VERSION ""

NS_ :

BS_:
BU_: ADU LBC Inverter
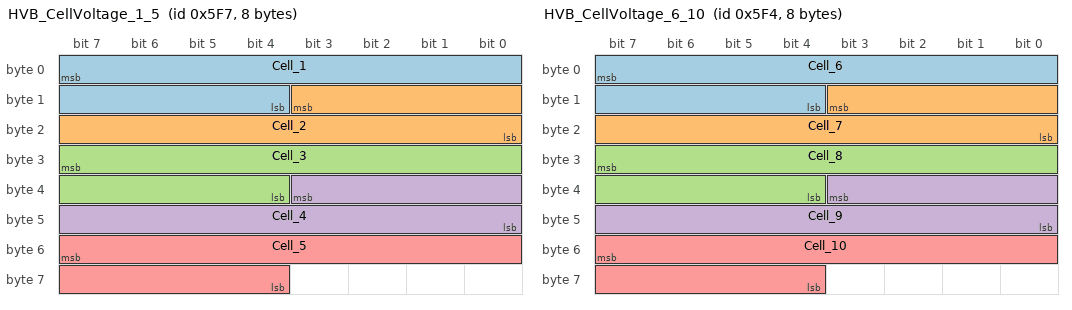
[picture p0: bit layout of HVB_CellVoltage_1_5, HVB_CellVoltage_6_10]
BO_ 1527 HVB_CellVoltage_1_5: 8 LBC
   SG_ Cell_1 : 7|12@0+ (0.001,2) [0|1] "Volts" LBC
   SG_ Cell_2 : 11|12@0+ (0.001,2) [0|1] "Volts" LBC
   SG_ Cell_3 : 31|12@0+ (0.001,2) [0|1] "Volts" LBC
   SG_ Cell_4 : 35|12@0+ (0.001,2) [0|1] "Volts" LBC
   SG_ Cell_5 : 55|12@0+ (0.001,2) [0|1] "Volts" LBC

BO_ 1524 HVB_CellVoltage_6_10: 8 LBC
   SG_ Cell_6 : 7|12@0+ (0.001,2) [0|1] "Volts" LBC
   SG_ Cell_7 : 11|12@0+ (0.001,2) [0|1] "Volts" LBC
   SG_ Cell_8 : 31|12@0+ (0.001,2) [0|1] "Volts" LBC
   SG_ Cell_9 : 35|12@0+ (0.001,2) [0|1] "Volts" LBC
   SG_ Cell_10 : 55|12@0+ (0.001,2) [0|1] "Volts" LBC

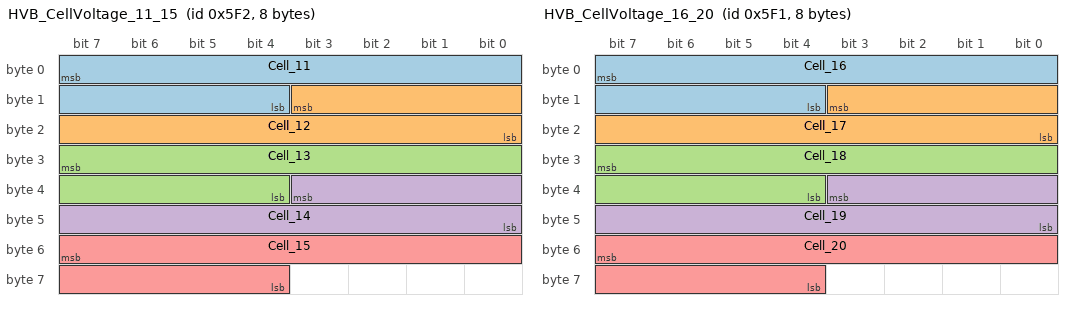
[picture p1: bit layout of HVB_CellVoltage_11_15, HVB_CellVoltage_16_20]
BO_ 1522 HVB_CellVoltage_11_15: 8 LBC
   SG_ Cell_11 : 7|12@0+ (0.001,2) [0|1] "Volts" LBC
   SG_ Cell_12 : 11|12@0+ (0.001,2) [0|1] "Volts" LBC
   SG_ Cell_13 : 31|12@0+ (0.001,2) [0|1] "Volts" LBC
   SG_ Cell_14 : 35|12@0+ (0.001,2) [0|1] "Volts" LBC
   SG_ Cell_15 : 55|12@0+ (0.001,2) [0|1] "Volts" LBC

BO_ 1521 HVB_CellVoltage_16_20: 8 LBC
   SG_ Cell_16 : 7|12@0+ (0.001,2) [0|1] "Volts" LBC
   SG_ Cell_17 : 11|12@0+ (0.001,2) [0|1] "Volts" LBC
   SG_ Cell_18 : 31|12@0+ (0.001,2) [0|1] "Volts" LBC
   SG_ Cell_19 : 35|12@0+ (0.001,2) [0|1] "Volts" LBC
   SG_ Cell_20 : 55|12@0+ (0.001,2) [0|1] "Volts" LBC

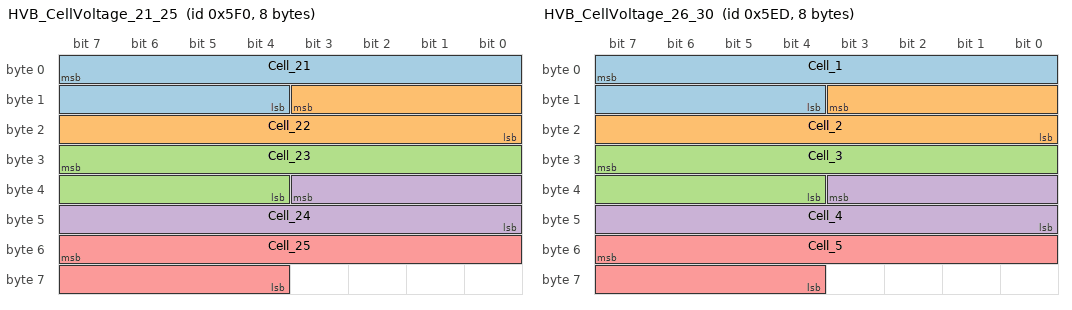
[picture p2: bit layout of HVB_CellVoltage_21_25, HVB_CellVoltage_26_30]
BO_ 1520 HVB_CellVoltage_21_25: 8 LBC
   SG_ Cell_21 : 7|12@0+ (0.001,2) [0|1] "Volts" LBC
   SG_ Cell_22 : 11|12@0+ (0.001,2) [0|1] "Volts" LBC
   SG_ Cell_23 : 31|12@0+ (0.001,2) [0|1] "Volts" LBC
   SG_ Cell_24 : 35|12@0+ (0.001,2) [0|1] "Volts" LBC
   SG_ Cell_25 : 55|12@0+ (0.001,2) [0|1] "Volts" LBC

BO_ 1517 HVB_CellVoltage_26_30: 8 LBC
   SG_ Cell_1 : 7|12@0+ (0.001,2) [0|1] "Volts" LBC
   SG_ Cell_2 : 11|12@0+ (0.001,2) [0|1] "Volts" LBC
   SG_ Cell_3 : 31|12@0+ (0.001,2) [0|1] "Volts" LBC
   SG_ Cell_4 : 35|12@0+ (0.001,2) [0|1] "Volts" LBC
   SG_ Cell_5 : 55|12@0+ (0.001,2) [0|1] "Volts" LBC

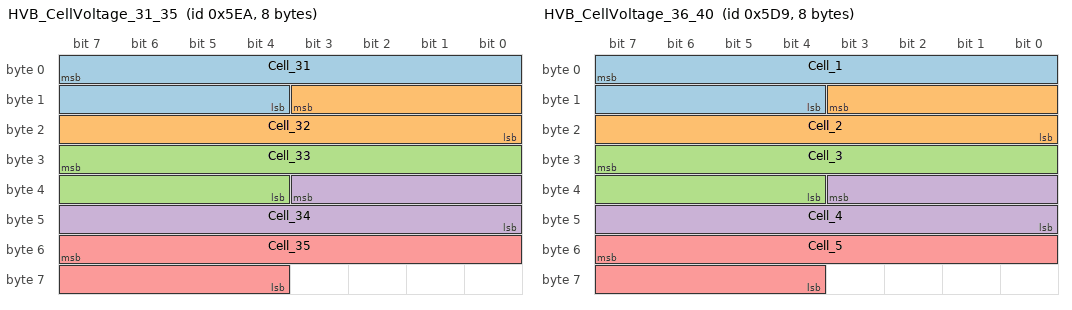
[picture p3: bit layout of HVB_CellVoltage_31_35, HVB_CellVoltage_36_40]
BO_ 1514 HVB_CellVoltage_31_35: 8 LBC
   SG_ Cell_31 : 7|12@0+ (0.001,2) [0|1] "Volts" LBC
   SG_ Cell_32 : 11|12@0+ (0.001,2) [0|1] "Volts" LBC
   SG_ Cell_33 : 31|12@0+ (0.001,2) [0|1] "Volts" LBC
   SG_ Cell_34 : 35|12@0+ (0.001,2) [0|1] "Volts" LBC
   SG_ Cell_35 : 55|12@0+ (0.001,2) [0|1] "Volts" LBC

BO_ 1497 HVB_CellVoltage_36_40: 8 LBC
   SG_ Cell_1 : 7|12@0+ (0.001,2) [0|1] "Volts" LBC
   SG_ Cell_2 : 11|12@0+ (0.001,2) [0|1] "Volts" LBC
   SG_ Cell_3 : 31|12@0+ (0.001,2) [0|1] "Volts" LBC
   SG_ Cell_4 : 35|12@0+ (0.001,2) [0|1] "Volts" LBC
   SG_ Cell_5 : 55|12@0+ (0.001,2) [0|1] "Volts" LBC

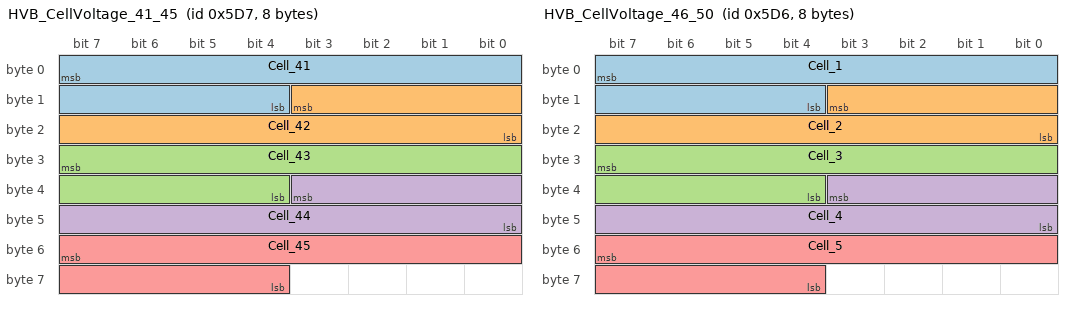
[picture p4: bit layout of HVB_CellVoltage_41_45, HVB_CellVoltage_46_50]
BO_ 1495 HVB_CellVoltage_41_45: 8 LBC
   SG_ Cell_41 : 7|12@0+ (0.001,2) [0|1] "Volts" LBC
   SG_ Cell_42 : 11|12@0+ (0.001,2) [0|1] "Volts" LBC
   SG_ Cell_43 : 31|12@0+ (0.001,2) [0|1] "Volts" LBC
   SG_ Cell_44 : 35|12@0+ (0.001,2) [0|1] "Volts" LBC
   SG_ Cell_45 : 55|12@0+ (0.001,2) [0|1] "Volts" LBC

BO_ 1494 HVB_CellVoltage_46_50: 8 LBC
   SG_ Cell_1 : 7|12@0+ (0.001,2) [0|1] "Volts" LBC
   SG_ Cell_2 : 11|12@0+ (0.001,2) [0|1] "Volts" LBC
   SG_ Cell_3 : 31|12@0+ (0.001,2) [0|1] "Volts" LBC
   SG_ Cell_4 : 35|12@0+ (0.001,2) [0|1] "Volts" LBC
   SG_ Cell_5 : 55|12@0+ (0.001,2) [0|1] "Volts" LBC

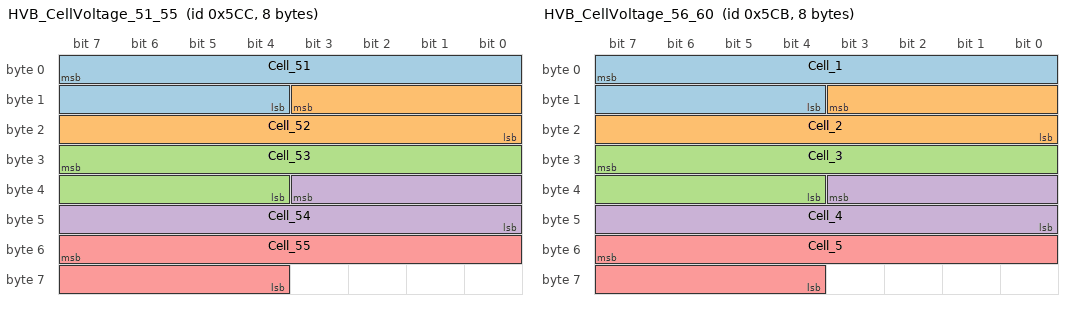
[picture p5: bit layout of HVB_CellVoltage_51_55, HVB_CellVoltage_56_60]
BO_ 1484 HVB_CellVoltage_51_55: 8 LBC
   SG_ Cell_51 : 7|12@0+ (0.001,2) [0|1] "Volts" LBC
   SG_ Cell_52 : 11|12@0+ (0.001,2) [0|1] "Volts" LBC
   SG_ Cell_53 : 31|12@0+ (0.001,2) [0|1] "Volts" LBC
   SG_ Cell_54 : 35|12@0+ (0.001,2) [0|1] "Volts" LBC
   SG_ Cell_55 : 55|12@0+ (0.001,2) [0|1] "Volts" LBC

BO_ 1483 HVB_CellVoltage_56_60: 8 LBC
   SG_ Cell_1 : 7|12@0+ (0.001,2) [0|1] "Volts" LBC
   SG_ Cell_2 : 11|12@0+ (0.001,2) [0|1] "Volts" LBC
   SG_ Cell_3 : 31|12@0+ (0.001,2) [0|1] "Volts" LBC
   SG_ Cell_4 : 35|12@0+ (0.001,2) [0|1] "Volts" LBC
   SG_ Cell_5 : 55|12@0+ (0.001,2) [0|1] "Volts" LBC

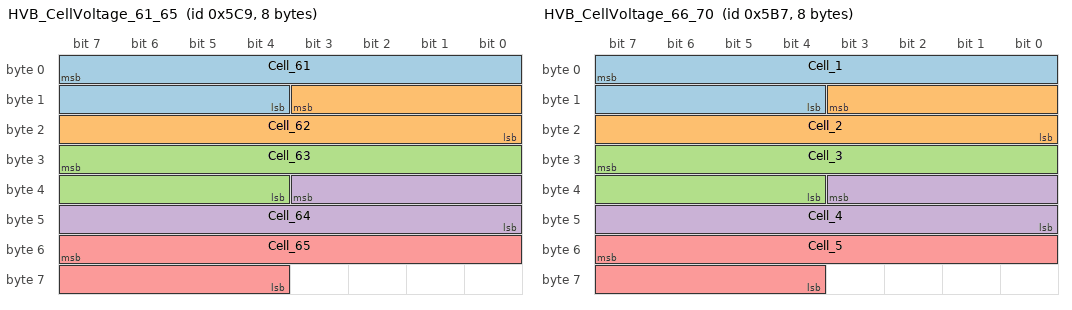
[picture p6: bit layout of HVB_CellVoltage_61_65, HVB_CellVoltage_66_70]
BO_ 1481 HVB_CellVoltage_61_65: 8 LBC
   SG_ Cell_61 : 7|12@0+ (0.001,2) [0|1] "Volts" LBC
   SG_ Cell_62 : 11|12@0+ (0.001,2) [0|1] "Volts" LBC
   SG_ Cell_63 : 31|12@0+ (0.001,2) [0|1] "Volts" LBC
   SG_ Cell_64 : 35|12@0+ (0.001,2) [0|1] "Volts" LBC
   SG_ Cell_65 : 55|12@0+ (0.001,2) [0|1] "Volts" LBC

BO_ 1463 HVB_CellVoltage_66_70: 8 LBC
   SG_ Cell_1 : 7|12@0+ (0.001,2) [0|1] "Volts" LBC
   SG_ Cell_2 : 11|12@0+ (0.001,2) [0|1] "Volts" LBC
   SG_ Cell_3 : 31|12@0+ (0.001,2) [0|1] "Volts" LBC
   SG_ Cell_4 : 35|12@0+ (0.001,2) [0|1] "Volts" LBC
   SG_ Cell_5 : 55|12@0+ (0.001,2) [0|1] "Volts" LBC

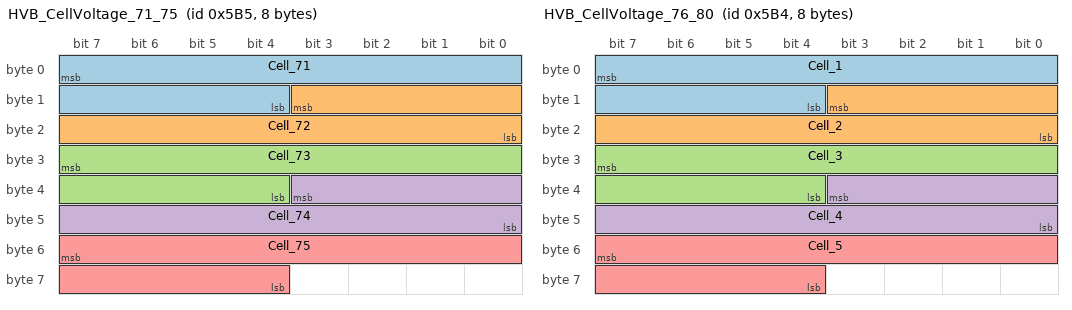
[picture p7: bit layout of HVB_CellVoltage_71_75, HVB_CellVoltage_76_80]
BO_ 1461 HVB_CellVoltage_71_75: 8 LBC
   SG_ Cell_71 : 7|12@0+ (0.001,2) [0|1] "Volts" LBC
   SG_ Cell_72 : 11|12@0+ (0.001,2) [0|1] "Volts" LBC
   SG_ Cell_73 : 31|12@0+ (0.001,2) [0|1] "Volts" LBC
   SG_ Cell_74 : 35|12@0+ (0.001,2) [0|1] "Volts" LBC
   SG_ Cell_75 : 55|12@0+ (0.001,2) [0|1] "Volts" LBC

BO_ 1460 HVB_CellVoltage_76_80: 8 LBC
   SG_ Cell_1 : 7|12@0+ (0.001,2) [0|1] "Volts" LBC
   SG_ Cell_2 : 11|12@0+ (0.001,2) [0|1] "Volts" LBC
   SG_ Cell_3 : 31|12@0+ (0.001,2) [0|1] "Volts" LBC
   SG_ Cell_4 : 35|12@0+ (0.001,2) [0|1] "Volts" LBC
   SG_ Cell_5 : 55|12@0+ (0.001,2) [0|1] "Volts" LBC

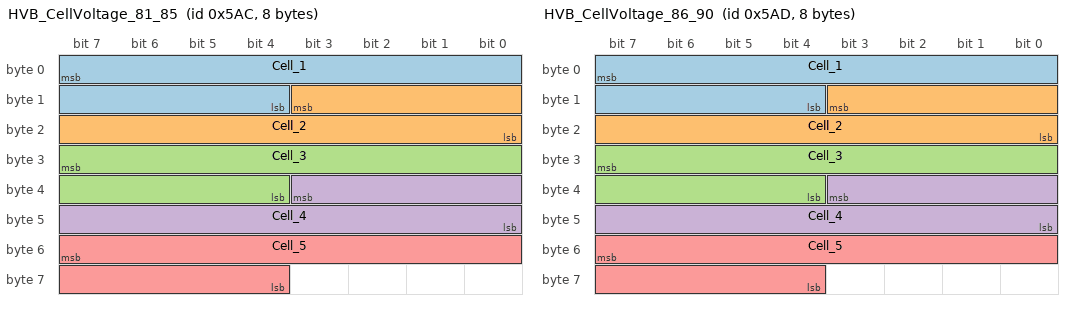
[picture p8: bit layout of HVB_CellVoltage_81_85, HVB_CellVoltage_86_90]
BO_ 1452 HVB_CellVoltage_81_85: 8 LBC
   SG_ Cell_1 : 7|12@0+ (0.001,2) [0|1] "Volts" LBC
   SG_ Cell_2 : 11|12@0+ (0.001,2) [0|1] "Volts" LBC
   SG_ Cell_3 : 31|12@0+ (0.001,2) [0|1] "Volts" LBC
   SG_ Cell_4 : 35|12@0+ (0.001,2) [0|1] "Volts" LBC
   SG_ Cell_5 : 55|12@0+ (0.001,2) [0|1] "Volts" LBC

BO_ 1453 HVB_CellVoltage_86_90: 8 LBC
   SG_ Cell_1 : 7|12@0+ (0.001,2) [0|1] "Volts" LBC
   SG_ Cell_2 : 11|12@0+ (0.001,2) [0|1] "Volts" LBC
   SG_ Cell_3 : 31|12@0+ (0.001,2) [0|1] "Volts" LBC
   SG_ Cell_4 : 35|12@0+ (0.001,2) [0|1] "Volts" LBC
   SG_ Cell_5 : 55|12@0+ (0.001,2) [0|1] "Volts" LBC

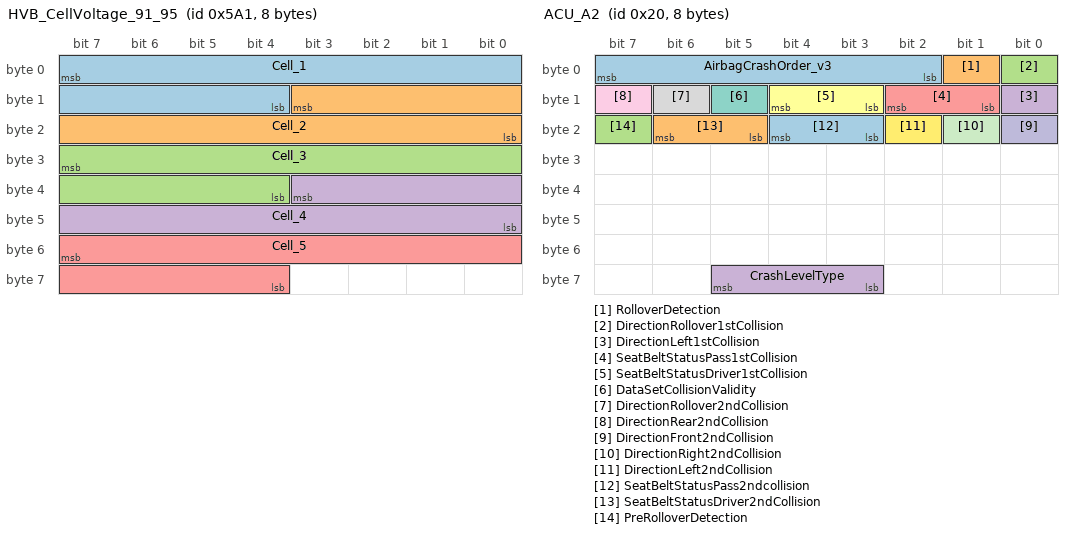
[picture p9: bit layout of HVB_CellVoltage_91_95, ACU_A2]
BO_ 1441 HVB_CellVoltage_91_95: 8 LBC
   SG_ Cell_1 : 7|12@0+ (0.001,2) [0|1] "Volts" LBC
   SG_ Cell_2 : 11|12@0+ (0.001,2) [0|1] "Volts" LBC
   SG_ Cell_3 : 31|12@0+ (0.001,2) [0|1] "Volts" LBC
   SG_ Cell_4 : 35|12@0+ (0.001,2) [0|1] "Volts" LBC
   SG_ Cell_5 : 55|12@0+ (0.001,2) [0|1] "Volts" LBC

BO_ 1501 HVB_CellVoltage_96: 8 LBC
   SG_ Cell_96 : 7|12@0+ (0.001,2) [0|1] "Volts" LBC

BO_ 32 ACU_A2: 8 ADU
   SG_ AirbagCrashOrder_v3 : 7|6@0+ (1,0) [0|1] "" Vector__XXX
   SG_ RolloverDetection : 1|1@0+ (1,0) [0|1] "" Vector__XXX
   SG_ DirectionRollover1stCollision : 0|1@0+ (1,0) [0|1] "" Vector__XXX
   SG_ DirectionLeft1stCollision : 8|1@0+ (1,0) [0|1] "" Vector__XXX
   SG_ SeatBeltStatusPass1stCollision : 10|2@0+ (1,0) [0|1] "" Vector__XXX
   SG_ SeatBeltStatusDriver1stCollision : 12|2@0+ (1,0) [0|1] "" Vector__XXX
   SG_ DataSetCollisionValidity : 13|1@0+ (1,0) [0|1] "" Vector__XXX
   SG_ DirectionRollover2ndCollision : 14|1@0+ (1,0) [0|1] "" Vector__XXX
   SG_ DirectionRear2ndCollision : 15|1@0+ (1,0) [0|1] "" Vector__XXX
   SG_ DirectionFront2ndCollision : 16|1@0+ (1,0) [0|1] "" Vector__XXX
   SG_ DirectionRight2ndCollision : 17|1@0+ (1,0) [0|1] "" Vector__XXX
   SG_ DirectionLeft2ndCollision : 18|1@0+ (1,0) [0|1] "" Vector__XXX
   SG_ SeatBeltStatusPass2ndcollision : 20|2@0+ (1,0) [0|1] "" Vector__XXX
   SG_ SeatBeltStatusDriver2ndCollision : 22|2@0+ (1,0) [0|1] "" Vector__XXX
   SG_ PreRolloverDetection : 23|1@0+ (1,0) [0|1] "" Vector__XXX
   SG_ CrashLevelType : 61|3@0+ (1,0) [0|1] "" Vector__XXX

BO_ 239 INVERTER_297: 8 Inverter
   SG_ Counter : 27|4@0+ (1,0) [0|1] "" Vector__XXX
   SG_ Checksum : 39|8@0+ (1,0) [0|1] "" Vector__XXX

BO_ 1198 LBC_UNKNOWN_4AE: 0 LBC

BO_ 1199 LBC_UNKNOWN_4AF: 0 LBC

BO_ 1243 LBC_MIN_MAX_CELL_VOLTS: 3 LBC
   SG_ Max_cell_volts : 7|12@0+ (0.001,1) [0|5] "v" Vector__XXX
   SG_ Min_cell_volts : 11|12@0+ (0.001,1) [0|1] "v" Vector__XXX

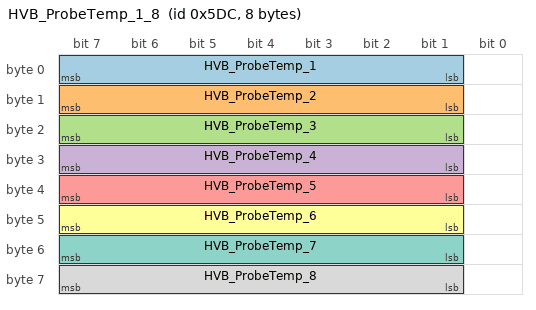
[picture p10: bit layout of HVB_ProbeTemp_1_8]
BO_ 1500 HVB_ProbeTemp_1_8: 8 LBC
   SG_ HVB_ProbeTemp_1 : 7|7@0+ (1,-40) [0|1] "C" Vector__XXX
   SG_ HVB_ProbeTemp_2 : 15|7@0+ (1,-40) [0|1] "C" Vector__XXX
   SG_ HVB_ProbeTemp_3 : 23|7@0+ (1,-40) [0|1] "C" Vector__XXX
   SG_ HVB_ProbeTemp_4 : 31|7@0+ (1,-40) [0|1] "C" Vector__XXX
   SG_ HVB_ProbeTemp_5 : 39|7@0+ (1,-40) [0|1] "C" Vector__XXX
   SG_ HVB_ProbeTemp_6 : 47|7@0+ (1,-40) [0|1] "C" Vector__XXX
   SG_ HVB_ProbeTemp_7 : 55|7@0+ (1,-40) [0|1] "C" Vector__XXX
   SG_ HVB_ProbeTemp_8 : 63|7@0+ (1,-40) [0|1] "C" Vector__XXX

BO_ 1007 LBC_UNKNOWN_3EF: 8 LBC
   SG_ Counter : 15|4@0+ (1,0) [0|1] "" Vector__XXX
   SG_ Checksum : 7|8@0+ (1,0) [0|1] "" Vector__XXX

BO_ 904 LBC_UNKNOWN_388: 8 LBC

BO_ 876 LBC_UNKNOWN_36C: 8 LBC
   SG_ Counter : 51|4@0+ (1,0) [0|1] "" Vector__XXX
   SG_ Checksum : 63|8@0+ (1,0) [0|1] "" Vector__XXX

BO_ 897 LBC_UNKNOWN_381_SOC_OR_KWH: 8 LBC

BO_ 882 LBC_UNKNOWN_372_STATIC: 8 LBC

BO_ 903 LBC_UNKNOWN_387_STATIC: 1 LBC

BO_ 248 LBC_CURRENT_VOLTAGE: 8 LBC
   SG_ Pack_Voltage : 22|12@0+ (0.1,0) [0|1] "V" Vector__XXX
   SG_ Current : 33|8@0+ (0.1,0) [0|15] "A" Vector__XXX

BO_ 898 LBC_UNKNOWN_382: 8 LBC

BO_ 1726 LBC_UNKNOWN_6BE: 8 LBC
   SG_ UNKNOWN_NUMBER : 7|8@0+ (0.1,0) [0|1] "v" Vector__XXX
   SG_ UNKNOWN_NUMBER_2 : 15|8@0+ (0.1,0) [0|1] "v" Vector__XXX

BO_ 1554 LBC_UNKNOWN_612: 0 LBC

BO_ 41 UNKNOWN_029: 6 Vector__XXX
   SG_ Counter : 19|4@0+ (1,0) [0|1] "" Vector__XXX
   SG_ Checksum : 31|8@0+ (1,0) [0|1] "" Vector__XXX

BO_ 238 INVERTER_0EE: 8 Inverter
   SG_ Counter : 51|4@0+ (1,0) [0|1] "" Vector__XXX
   SG_ Checksum : 63|8@0+ (1,0) [0|1] "" Vector__XXX

BO_ 240 INVERTER_0F0: 8 Inverter
   SG_ Counter : 27|4@0+ (1,0) [0|1] "" Vector__XXX
   SG_ Checksum : 39|8@0+ (1,0) [0|1] "" Vector__XXX

BO_ 245 UNKNOWN_0F5: 8 Vector__XXX
   SG_ Counter : 11|4@0+ (1,0) [0|1] "" Vector__XXX
   SG_ Checksum : 23|8@0+ (1,0) [0|1] "" Vector__XXX

BO_ 253 UNKNOWN_0FD: 8 Vector__XXX
   SG_ Counter : 15|4@0+ (1,0) [0|1] "" Vector__XXX
   SG_ Checksum : 7|8@0+ (1,0) [0|1] "" Vector__XXX

BO_ 269 UNKNOWN_10D: 4 Vector__XXX
   SG_ Counter : 15|4@0+ (1,0) [0|1] "" Vector__XXX
   SG_ Checksum : 7|8@0+ (1,0) [0|1] "" Vector__XXX

BO_ 375 UNKNOWN_177: 8 Vector__XXX
   SG_ Counter : 15|4@0+ (1,0) [0|1] "" Vector__XXX
   SG_ Checksum : 7|8@0+ (1,0) [0|1] "" Vector__XXX

BO_ 307 UNKNOWN_133: 8 Vector__XXX
   SG_ Counter : 21|4@0+ (1,0) [0|1] "" Vector__XXX
   SG_ Checksum : 31|8@0+ (1,0) [0|1] "" Vector__XXX

BO_ 306 UNKNOWN_132: 8 Vector__XXX
   SG_ Counter : 35|4@0+ (1,0) [0|1] "" Vector__XXX

BA_DEF_ BO_ "GenMsgBackgroundColor" STRING ;
BA_DEF_ BO_ "GenMsgForegroundColor" STRING ;
BA_ "GenMsgForegroundColor" BO_ 32 "#000000";
BA_ "GenMsgForegroundColor" BO_ 239 "#b47800";
BA_ "GenMsgForegroundColor" BO_ 41 "#aaaa00";
BA_ "GenMsgForegroundColor" BO_ 238 "#aaaa00";
BA_ "GenMsgForegroundColor" BO_ 240 "#aa5500";
BA_ "GenMsgForegroundColor" BO_ 245 "#aaaa00";
BA_ "GenMsgForegroundColor" BO_ 253 "#aaaa00";
BA_ "GenMsgForegroundColor" BO_ 269 "#aaaa00";
BA_ "GenMsgForegroundColor" BO_ 375 "#aaaa00";
BA_ "GenMsgForegroundColor" BO_ 307 "#aaaa00";
BA_ "GenMsgForegroundColor" BO_ 306 "#aaaa00";
BA_DEF_DEF_ "GenMsgBackgroundColor" "#ffffff";
BA_DEF_DEF_ "GenMsgForegroundColor" "#aa0000";
CM_ BU_ LBC "Lithim Battery Controller";
CM_ BO_ 898 " ";
VAL_ 32 AirbagCrashOrder_v3 0 "Crash_not_detected" 15 "Medium_crash" 31 "Violent_crash" 47 "Rear_crash";
VAL_ 32 RolloverDetection 0 "Rollover_not_detected" 1 "Rollover_detected" 0 "" 0 "";
VAL_ 32 DirectionRollover1stCollision 0 "No_detect" 1 "Detect" 0 "" 0 "";
VAL_ 32 DirectionLeft1stCollision 0 "No_Detect" 1 "Detect" 0 "" 0 "";
VAL_ 32 SeatBeltStatusPass1stCollision 0 "SB_Not_monitored" 1 "SB_unfastened" 2 "SB_fastened" 3 "Unavailable";
VAL_ 32 SeatBeltStatusDriver1stCollision 0 "SB_Not_monitored" 1 "SB_unfastened" 2 "SB_fastened" 3 "Unavailable";
VAL_ 32 DataSetCollisionValidity 0 "First_collision" 1 "Second_collision" 2 "" 3 "";
VAL_ 32 DirectionRollover2ndCollision 0 "No_detect" 1 "Detect" 0 "" 0 "";
VAL_ 32 DirectionRear2ndCollision 0 "No_detect" 1 "Detect" 0 "" 0 "";
VAL_ 32 DirectionFront2ndCollision 0 "No_detect" 1 "Detect" 0 "" 0 "";
VAL_ 32 DirectionRight2ndCollision 0 "No_detect" 1 "Detect" 0 "" 0 "";
VAL_ 32 DirectionLeft2ndCollision 0 "No_detect" 1 "Detect" 0 "" 0 "";
VAL_ 32 SeatBeltStatusPass2ndcollision 0 "SB_Not_monitored" 1 "SB_unfastened" 2 "SB_fastened" 3 "Unavailable";
VAL_ 32 SeatBeltStatusDriver2ndCollision 0 "SB_Not_monitored" 1 "SB_unfastened" 2 "SB_fastened" 3 "Unavailable";
VAL_ 32 PreRolloverDetection 0 "Rollover_not_detected" 1 "Rollover_detected" 0 "" 0 "";
VAL_ 32 CrashLevelType 0 "No_crash_or_confirmed_light_crash" 1 "Reserved_for_safety" 2 "Reserved_for_safety2" 3 "Reserved_for_safety3" 4 "Reserved_for_safety4" 5 "Reserved_for_safety5" 6 "Reserved_for_safety6" 7 "Possible_heavy_crash_or_confirmed_heavy_crash";
